VERSION ""

NS_ :

BS_: 500

BU_: Vector__XXX

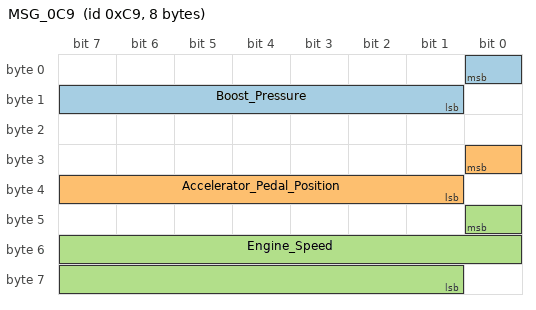
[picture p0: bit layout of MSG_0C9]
BO_ 201 MSG_0C9: 8 Vector__XXX
 SG_ Boost_Pressure : 0|8@0- (1,0) [0|0] "kPaG" Vector__XXX
 SG_ Accelerator_Pedal_Position : 24|8@0+ (0.392156862745,0) [0|0] "%" Vector__XXX
 SG_ Engine_Speed : 40|16@0+ (0.25,0) [0|10000] "rpm" Vector__XXX

BO_ 241 MSG_0F1: 8 Vector__XXX
 SG_ Brake_Position : 48|8@0+ (0.255,0) [0|0] "%" Vector__XXX

BO_ 401 MSG_191: 8 Vector__XXX
 SG_ Throttle_Position : 8|8@0+ (0.392156862745,0) [0|0] "%" Vector__XXX
 SG_ Manifold_Pressure : 32|16@0+ (0.0392,0) [0|110] "kPa" Vector__XXX

BO_ 405 MSG_195: 8 Vector__XXX
 SG_ Mass_Air_Flow : 0|16@0+ (0.01,0) [0|250] "" Vector__XXX

BO_ 451 MSG_1C3: 8 Vector__XXX
 SG_ Engine_Torque : 48|12@0+ (0.5,-848) [0|0] "Nm" Vector__XXX

BO_ 485 MSG_1E5: 8 Vector__XXX
 SG_ Steering_Angle : 40|16@0- (0.002,0) [-20|20] "��" Vector__XXX

BO_ 840 MSG_348: 8 Vector__XXX
 SG_ Wheel_Speed_RR_kph : 32|14@0+ (0.0315,0) [0|250] "km/h" Vector__XXX
 SG_ Wheel_Speed_RR_mph : 32|14@0+ (0.0195615,0) [0|155.25] "mph" Vector__XXX
 SG_ Wheel_Speed_RL_kph : 48|14@0+ (0.0315,0) [0|250] "km/h" Vector__XXX
 SG_ Wheel_Speed_RL_mph : 48|14@0+ (0.0195615,0) [0|155.25] "mph" Vector__XXX

BO_ 842 MSG_34A: 8 Vector__XXX
 SG_ Wheel_Speed_FR_kph : 32|14@0+ (0.0315,0) [0|250] "km/h" Vector__XXX
 SG_ Wheel_Speed_FR_mph : 32|14@0+ (0.0195615,0) [0|155.25] "mph" Vector__XXX
 SG_ Wheel_Speed_FL_kph : 48|14@0+ (0.0315,0) [0|250] "km/h" Vector__XXX
 SG_ Wheel_Speed_FL_mph : 48|14@0+ (0.0195615,0) [0|155.25] "mph" Vector__XXX

BO_ 1217 MSG_4C1: 8 Vector__XXX
 SG_ Intake_Air_Temperature : 32|8@0+ (1,-40) [0|0] "��C" Vector__XXX
 SG_ Coolant_Temperature : 40|8@0+ (1,-40) [0|0] "��C" Vector__XXX
